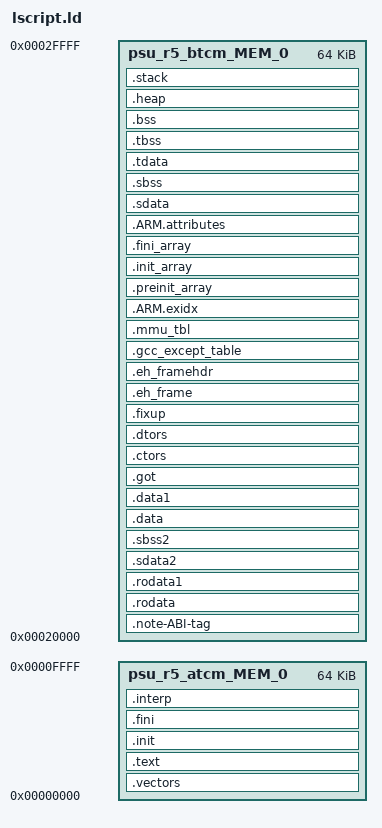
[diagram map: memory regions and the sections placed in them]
/******************************************************************************
 *
 * Copyright (C) 2017 Xilinx, Inc.  All rights reserved.
 *
 * Redistribution and use in source and binary forms, with or without
 * modification, are permitted provided that the following conditions are met:
 *
 * 1. Redistributions of source code must retain the above copyright notice,
 *    this list of conditions and the following disclaimer.
 *
 * 2. Redistributions in binary form must reproduce the above copyright notice,
 *    this list of conditions and the following disclaimer in the documentation
 *    and/or other materials provided with the distribution.
 *
 * 3. Neither the name of Xilinx nor the names of its contributors may be used
 *    to endorse or promote products derived from this software without
 *    specific prior written permission.
 *
 * THIS SOFTWARE IS PROVIDED BY THE COPYRIGHT HOLDERS AND CONTRIBUTORS "AS IS"
 * AND ANY EXPRESS OR IMPLIED WARRANTIES, INCLUDING, BUT NOT LIMITED TO, THE
 * IMPLIED WARRANTIES OF MERCHANTABILITY AND FITNESS FOR A PARTICULAR PURPOSE
 * ARE DISCLAIMED. IN NO EVENT SHALL THE COPYRIGHT HOLDER OR CONTRIBUTORS BE
 * LIABLE FOR ANY DIRECT, INDIRECT, INCIDENTAL, SPECIAL, EXEMPLARY, OR
 * CONSEQUENTIAL DAMAGES (INCLUDING, BUT NOT LIMITED TO, PROCUREMENT OF
 * SUBSTITUTE GOODS OR SERVICES; LOSS OF USE, DATA, OR PROFITS; OR BUSINESS
 * INTERRUPTION) HOWEVER CAUSED AND ON ANY THEORY OF LIABILITY, WHETHER IN
 * CONTRACT, STRICT LIABILITY, OR TORT (INCLUDING NEGLIGENCE OR OTHERWISE)
 * ARISING IN ANY WAY OUT OF THE USE OF THIS SOFTWARE, EVEN IF ADVISED OF THE
 * POSSIBILITY OF SUCH DAMAGE.
 *
 ******************************************************************************/

_STACK_SIZE = DEFINED(_STACK_SIZE) ? _STACK_SIZE : 0x2000;
_HEAP_SIZE = DEFINED(_HEAP_SIZE) ? _HEAP_SIZE : 0x4000;

_ABORT_STACK_SIZE = DEFINED(_ABORT_STACK_SIZE) ? _ABORT_STACK_SIZE : 1024;
_SUPERVISOR_STACK_SIZE = DEFINED(_SUPERVISOR_STACK_SIZE) ? _SUPERVISOR_STACK_SIZE : 2048;
_IRQ_STACK_SIZE = DEFINED(_IRQ_STACK_SIZE) ? _IRQ_STACK_SIZE : 1024;
_FIQ_STACK_SIZE = DEFINED(_FIQ_STACK_SIZE) ? _FIQ_STACK_SIZE : 1024;
_UNDEF_STACK_SIZE = DEFINED(_UNDEF_STACK_SIZE) ? _UNDEF_STACK_SIZE : 1024;

/* Define Memories in the system */

MEMORY
{
   psu_r5_atcm_MEM_0 : ORIGIN = 0x0, LENGTH = 0x10000
   psu_r5_btcm_MEM_0 : ORIGIN = 0x20000, LENGTH = 0x10000
}

/* Specify the default entry point to the program */

ENTRY(_boot)

/* Define the sections, and where they are mapped in memory */

SECTIONS
{
.vectors : {
   KEEP (*(.vectors))
   *(.boot)
} > psu_r5_atcm_MEM_0

.text : {
   *(.text)
   *(.text.*)
   *(.gnu.linkonce.t.*)
   *(.plt)
   *(.gnu_warning)
   *(.gcc_execpt_table)
   *(.glue_7)
   *(.glue_7t)
   *(.vfp11_veneer)
   *(.ARM.extab)
   *(.gnu.linkonce.armextab.*)
} > psu_r5_atcm_MEM_0

.init : {
   KEEP (*(.init))
} > psu_r5_atcm_MEM_0

.fini : {
   KEEP (*(.fini))
} > psu_r5_atcm_MEM_0

.interp : {
   KEEP (*(.interp))
} > psu_r5_atcm_MEM_0

.note-ABI-tag : {
   KEEP (*(.note-ABI-tag))
} > psu_r5_btcm_MEM_0

.rodata : {
   __rodata_start = .;
   *(.rodata)
   *(.rodata.*)
   *(.gnu.linkonce.r.*)
   __rodata_end = .;
} > psu_r5_btcm_MEM_0

.rodata1 : {
   __rodata1_start = .;
   *(.rodata1)
   *(.rodata1.*)
   __rodata1_end = .;
} > psu_r5_btcm_MEM_0

.sdata2 : {
   __sdata2_start = .;
   *(.sdata2)
   *(.sdata2.*)
   *(.gnu.linkonce.s2.*)
   __sdata2_end = .;
} > psu_r5_btcm_MEM_0

.sbss2 : {
   __sbss2_start = .;
   *(.sbss2)
   *(.sbss2.*)
   *(.gnu.linkonce.sb2.*)
   __sbss2_end = .;
} > psu_r5_btcm_MEM_0

.data : {
   __data_start = .;
   *(.data)
   *(.data.*)
   *(.gnu.linkonce.d.*)
   *(.jcr)
   *(.got)
   *(.got.plt)
   __data_end = .;
} > psu_r5_btcm_MEM_0

.data1 : {
   __data1_start = .;
   *(.data1)
   *(.data1.*)
   __data1_end = .;
} > psu_r5_btcm_MEM_0

.got : {
   *(.got)
} > psu_r5_btcm_MEM_0

.ctors : {
   __CTOR_LIST__ = .;
   ___CTORS_LIST___ = .;
   KEEP (*crtbegin.o(.ctors))
   KEEP (*(EXCLUDE_FILE(*crtend.o) .ctors))
   KEEP (*(SORT(.ctors.*)))
   KEEP (*(.ctors))
   __CTOR_END__ = .;
   ___CTORS_END___ = .;
} > psu_r5_btcm_MEM_0

.dtors : {
   __DTOR_LIST__ = .;
   ___DTORS_LIST___ = .;
   KEEP (*crtbegin.o(.dtors))
   KEEP (*(EXCLUDE_FILE(*crtend.o) .dtors))
   KEEP (*(SORT(.dtors.*)))
   KEEP (*(.dtors))
   __DTOR_END__ = .;
   ___DTORS_END___ = .;
} > psu_r5_btcm_MEM_0

.fixup : {
   __fixup_start = .;
   *(.fixup)
   __fixup_end = .;
} > psu_r5_btcm_MEM_0

.eh_frame : {
   *(.eh_frame)
} > psu_r5_btcm_MEM_0

.eh_framehdr : {
   __eh_framehdr_start = .;
   *(.eh_framehdr)
   __eh_framehdr_end = .;
} > psu_r5_btcm_MEM_0

.gcc_except_table : {
   *(.gcc_except_table)
} > psu_r5_btcm_MEM_0

.mmu_tbl (ALIGN(16384)) : {
   __mmu_tbl_start = .;
   *(.mmu_tbl)
   __mmu_tbl_end = .;
} > psu_r5_btcm_MEM_0

.ARM.exidx : {
   __exidx_start = .;
   *(.ARM.exidx*)
   *(.gnu.linkonce.armexidix.*.*)
   __exidx_end = .;
} > psu_r5_btcm_MEM_0

.preinit_array : {
   __preinit_array_start = .;
   KEEP (*(SORT(.preinit_array.*)))
   KEEP (*(.preinit_array))
   __preinit_array_end = .;
} > psu_r5_btcm_MEM_0

.init_array : {
   __init_array_start = .;
   KEEP (*(SORT(.init_array.*)))
   KEEP (*(.init_array))
   __init_array_end = .;
} > psu_r5_btcm_MEM_0

.fini_array : {
   __fini_array_start = .;
   KEEP (*(SORT(.fini_array.*)))
   KEEP (*(.fini_array))
   __fini_array_end = .;
} > psu_r5_btcm_MEM_0

.ARM.attributes : {
   __ARM.attributes_start = .;
   *(.ARM.attributes)
   __ARM.attributes_end = .;
} > psu_r5_btcm_MEM_0

.sdata : {
   __sdata_start = .;
   *(.sdata)
   *(.sdata.*)
   *(.gnu.linkonce.s.*)
   __sdata_end = .;
} > psu_r5_btcm_MEM_0

.sbss (NOLOAD) : {
   __sbss_start = .;
   *(.sbss)
   *(.sbss.*)
   *(.gnu.linkonce.sb.*)
   __sbss_end = .;
} > psu_r5_btcm_MEM_0

.tdata : {
   __tdata_start = .;
   *(.tdata)
   *(.tdata.*)
   *(.gnu.linkonce.td.*)
   __tdata_end = .;
} > psu_r5_btcm_MEM_0

.tbss : {
   __tbss_start = .;
   *(.tbss)
   *(.tbss.*)
   *(.gnu.linkonce.tb.*)
   __tbss_end = .;
} > psu_r5_btcm_MEM_0

.bss (NOLOAD) : {
   . = ALIGN(4);
   __bss_start__ = .;
   *(.bss)
   *(.bss.*)
   *(.gnu.linkonce.b.*)
   *(COMMON)
   . = ALIGN(4);
   __bss_end__ = .;
} > psu_r5_btcm_MEM_0

_SDA_BASE_ = __sdata_start + ((__sbss_end - __sdata_start) / 2 );

_SDA2_BASE_ = __sdata2_start + ((__sbss2_end - __sdata2_start) / 2 );

/* Generate Stack and Heap definitions */

.heap (NOLOAD) : {
   . = ALIGN(16);
   _heap = .;
   HeapBase = .;
   _heap_start = .;
   . += _HEAP_SIZE;
   _heap_end = .;
   HeapLimit = .;
} > psu_r5_btcm_MEM_0

.stack (NOLOAD) : {
   . = ALIGN(16);
   _stack_end = .;
   . += _STACK_SIZE;
   _stack = .;
   __stack = _stack;
   . = ALIGN(16);
   _irq_stack_end = .;
   . += _IRQ_STACK_SIZE;
   __irq_stack = .;
   _supervisor_stack_end = .;
   . += _SUPERVISOR_STACK_SIZE;
   . = ALIGN(16);
   __supervisor_stack = .;
   _abort_stack_end = .;
   . += _ABORT_STACK_SIZE;
   . = ALIGN(16);
   __abort_stack = .;
   _fiq_stack_end = .;
   . += _FIQ_STACK_SIZE;
   . = ALIGN(16);
   __fiq_stack = .;
   _undef_stack_end = .;
   . += _UNDEF_STACK_SIZE;
   . = ALIGN(16);
   __undef_stack = .;
} > psu_r5_btcm_MEM_0

_end = .;
}
